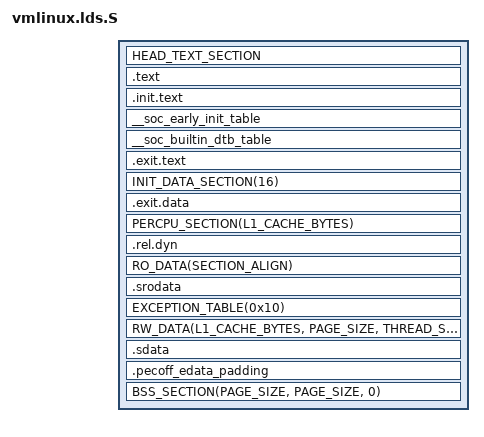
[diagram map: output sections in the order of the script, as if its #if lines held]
FASTVC-BENCH-CORPUS:linux-main-100k-v1-e0bd41dc-8e12-4f1b-978d-a3645ae59da0
/* SPDX-License-Identifier: GPL-2.0-only */
/*
 * Copyright (C) 2012 Regents of the University of California
 * Copyright (C) 2017 SiFive
 */

#define LOAD_OFFSET PAGE_OFFSET
#include <asm/vmlinux.lds.h>
#include <asm/page.h>
#include <asm/cache.h>
#include <asm/thread_info.h>
#include <asm/set_memory.h>
#include "image-vars.h"

#include <linux/sizes.h>
OUTPUT_ARCH(riscv)
ENTRY(_start)

jiffies = jiffies_64;

PECOFF_SECTION_ALIGNMENT = 0x1000;
PECOFF_FILE_ALIGNMENT = 0x200;

SECTIONS
{
	/* Beginning of code and text segment */
	. = LOAD_OFFSET;
	_start = .;
	HEAD_TEXT_SECTION
	. = ALIGN(PAGE_SIZE);

	.text : {
		_text = .;
		_stext = .;
		TEXT_TEXT
		SCHED_TEXT
		CPUIDLE_TEXT
		LOCK_TEXT
		KPROBES_TEXT
		ENTRY_TEXT
		IRQENTRY_TEXT
		SOFTIRQENTRY_TEXT
		*(.fixup)
		_etext = .;
	}

	. = ALIGN(SECTION_ALIGN);
	__init_begin = .;
	__init_text_begin = .;
	.init.text : AT(ADDR(.init.text) - LOAD_OFFSET) ALIGN(SECTION_ALIGN) { \
		_sinittext = .;						\
		INIT_TEXT						\
		_einittext = .;						\
	}

	. = ALIGN(8);
	__soc_early_init_table : {
		__soc_early_init_table_start = .;
		KEEP(*(__soc_early_init_table))
		__soc_early_init_table_end = .;
	}
	__soc_builtin_dtb_table : {
		__soc_builtin_dtb_table_start = .;
		KEEP(*(__soc_builtin_dtb_table))
		__soc_builtin_dtb_table_end = .;
	}
	/* we have to discard exit text and such at runtime, not link time */
	.exit.text :
	{
		EXIT_TEXT
	}

	__init_text_end = .;
	. = ALIGN(SECTION_ALIGN);
#ifdef CONFIG_EFI
	. = ALIGN(PECOFF_SECTION_ALIGNMENT);
	__pecoff_text_end = .;
/* bench 14754.0.0 c3e828a25689 */
/* bench 14754.0.1 abb0ccccb824 */
/* bench 14754.0.2 09308cb2c285 */
/* bench 14754.0.3 0199ab7e2470 */
/* bench 14754.0.4 7bdd40290de2 */
/* bench 27761.1.0 131fa57b378a */
/* bench 27761.1.1 dcdbde36c4db */
/* bench 27761.1.2 ece2bfc075b3 */
/* bench 27761.1.3 1b4daed2010e */
/* bench 27761.1.4 399ac425c7df */
/* bench 27761.1.5 4b52ba1fe57d */
/* bench 27761.1.6 44a944d7cb14 */
/* bench 27761.1.7 46cc0e82a3d4 */
/* bench 14754.0.6 4c286c7d2504 */
/* bench 14754.0.7 4d8c7ba38139 */
/* bench 14754.0.8 fc3495d84241 */
/* bench 14754.0.9 ad21dbe41e67 */
/* bench 14754.0.10 15ddeb139b17 */
/* bench 14754.0.11 cbb883a65914 */
/* bench 14754.0.12 828fb85d9e4c */
	INIT_DATA_SECTION(16)
	.exit.data :
	{
		EXIT_DATA
	}
	PERCPU_SECTION(L1_CACHE_BYTES)

	.rel.dyn : {
		*(.rel.dyn*)
	}
/* bench 388.0.0 b54ef054c574 */
/* bench 388.0.1 48aca51d29f4 */

	/* Start of data section */
	_sdata = .;
	RO_DATA(SECTION_ALIGN)
	.srodata : {
		*(.srodata*)
	}

	EXCEPTION_TABLE(0x10)

	. = ALIGN(SECTION_ALIGN);
	_data = .;

	RW_DATA(L1_CACHE_BYTES, PAGE_SIZE, THREAD_SIZE)
	.sdata : {
		__global_pointer$ = . + 0x800;
		*(.sdata*)
	}
/* bench 17913.0.0 20cd34368525 */
/* bench 17913.0.1 42817421b37a */
/* bench 17913.0.2 1b51e603c5a0 */
/* bench 17913.0.3 2eb0271fea70 */
/* bench 17913.0.4 a3f6eaf5e93c */
/* bench 17913.0.5 21fdd7f7ba7b */
	.pecoff_edata_padding : { BYTE(0); . = ALIGN(PECOFF_FILE_ALIGNMENT); }
	__pecoff_data_raw_size = ABSOLUTE(. - __pecoff_text_end);
#endif

	/* End of data section */
	_edata = .;

	BSS_SECTION(PAGE_SIZE, PAGE_SIZE, 0)

#ifdef CONFIG_EFI
	. = ALIGN(PECOFF_SECTION_ALIGNMENT);
	__pecoff_data_virt_size = ABSOLUTE(. - __pecoff_text_end);
#endif
	_end = .;

	STABS_DEBUG
	DWARF_DEBUG
	ELF_DETAILS

	DISCARDS
}
